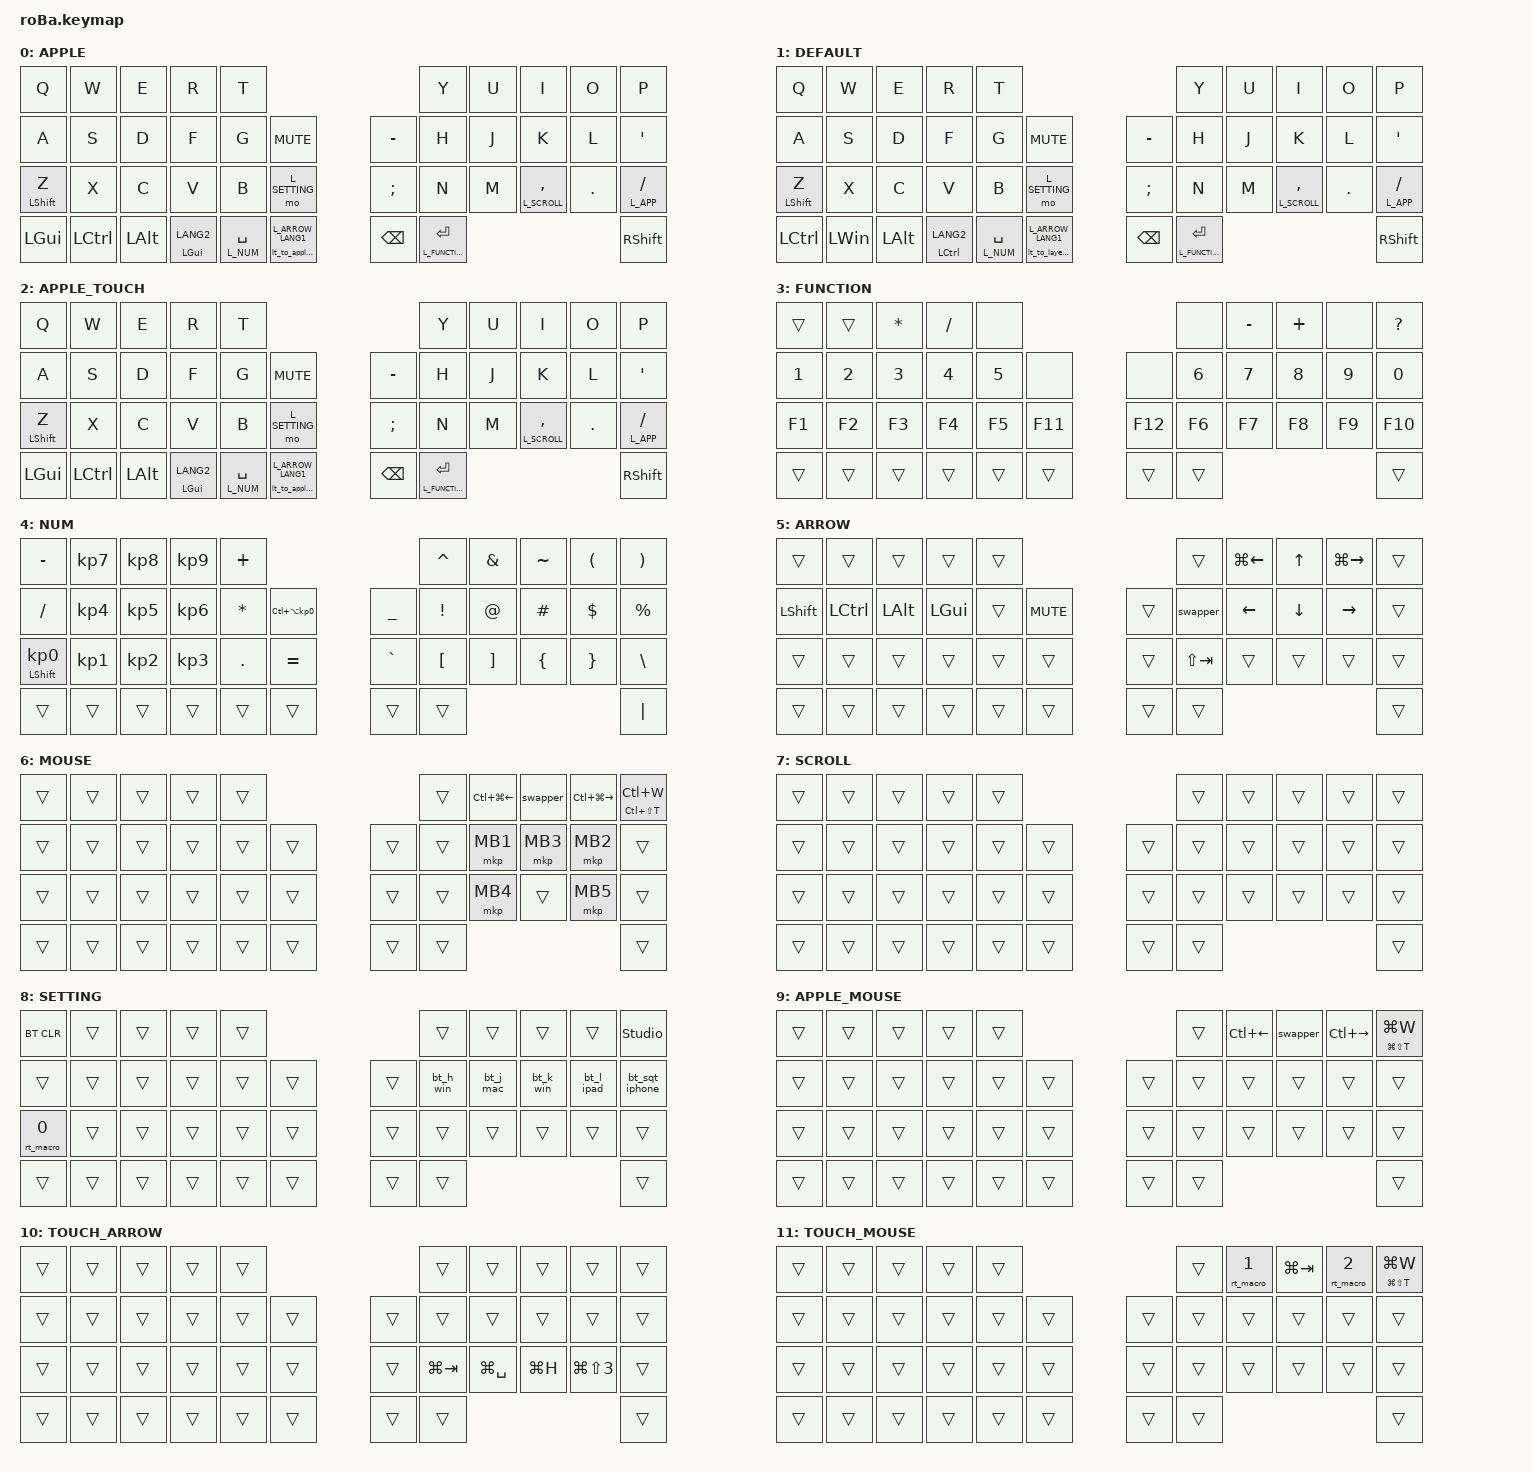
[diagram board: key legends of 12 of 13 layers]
#include <behaviors/runtime-sensor-rotate.dtsi>
#include <behaviors.dtsi>
#include <dt-bindings/zmk/bt.h>
#include <dt-bindings/zmk/keys.h>
#include <dt-bindings/zmk/pointing.h>

#undef ZMK_POINTING_DEFAULT_SCRL_VAL

#define ZMK_POINTING_DEFAULT_SCRL_VAL 80
#define L_DEFAULT      1
#define L_APPLE        0
#define L_APPLE_TOUCH  2
#define L_FUNCTION     3
#define L_NUM          4
#define L_ARROW        5
#define L_MOUSE        6
#define L_SCROLL       7
#define L_SETTING      8
#define L_APPLEMOUSE   9
#define L_TOUCH_ARROW  10
#define L_TOUCH_MOUSE  11
#define L_APP          12

&mt {
    flavor = "balanced";
    quick-tap-ms = <0>;
};

&trackball {
    automouse-layer = <L_MOUSE>;
    scroll-layers = <L_SCROLL>;

    // arrows {
    //     layers = <3>;
    //     bindings =
    //         <&kp RIGHT_ARROW>,
    //         <&kp LEFT_ARROW>,
    //         <&kp UP_ARROW>,
    //         <&kp DOWN_ARROW>;
    //     tick = <10>;
    //     wait-ms = <5>;
    //     tap-ms = <5>;
    // };
};

/ {
    combos {
        compatible = "zmk,runtime-combos";

        tab {
            bindings = <&kp TAB>;
            key-positions = <11 10>;
        };

        esc {
            bindings = <&kp ESCAPE>;
            key-positions = <0 1>;
        };

        backspace {
            bindings = <&kp BACKSPACE>;
            key-positions = <9 8>;
        };

        delete {
            bindings = <&kp DELETE>;
            key-positions = <20 21>;
        };

        redo_win {
            bindings = <&kp LC(LS(Z))>;
            key-positions = <22 23 24>;
            layers = <L_DEFAULT L_MOUSE>;
        };

        redo_apple {
            bindings = <&kp LG(LS(Z))>;
            key-positions = <22 23 24>;
            layers = <L_APPLE L_APPLEMOUSE L_APPLE_TOUCH L_TOUCH_MOUSE>;
        };
    };

    macros {
        to_layer_0: to_layer_0 {
            compatible = "zmk,behavior-macro-one-param";
            #binding-cells = <1>;
            bindings = <&to L_DEFAULT &macro_param_1to1 &kp MACRO_PLACEHOLDER>;
            label = "TO_LAYER_0";
        };

        to_apple_default: to_apple_default {
            compatible = "zmk,behavior-macro-one-param";
            #binding-cells = <1>;
            bindings = <&to L_APPLE &macro_param_1to1 &kp MACRO_PLACEHOLDER>;
            label = "TO_APPLE_DEFAULT";
        };

        to_apple_touch: to_apple_touch {
            compatible = "zmk,behavior-macro-one-param";
            #binding-cells = <1>;
            bindings = <&to L_APPLE_TOUCH &macro_param_1to1 &kp MACRO_PLACEHOLDER>;
            label = "TO_APPLE_TOUCH";
        };

        // BT profile -> base-layer routing. Key position fixed (H/J/K/L/SQT),
        // BT_SEL number fixed; only the &to base-layer differs (案B 2026-06-24).

        bt_h_win: bt_h_win {
            compatible = "zmk,behavior-macro";
            #binding-cells = <0>;
            bindings = <&bt BT_SEL 4 &to L_DEFAULT>;
            label = "BT_H_WIN";
        };

        bt_j_mac: bt_j_mac {
            compatible = "zmk,behavior-macro";
            #binding-cells = <0>;
            bindings = <&bt BT_SEL 0 &to L_APPLE>;
            label = "BT_J_MAC";
        };

        bt_k_win: bt_k_win {
            compatible = "zmk,behavior-macro";
            #binding-cells = <0>;
            bindings = <&bt BT_SEL 1 &to L_DEFAULT>;
            label = "BT_K_WIN";
        };

        bt_l_ipad: bt_l_ipad {
            compatible = "zmk,behavior-macro";
            #binding-cells = <0>;
            bindings = <&bt BT_SEL 2 &to L_APPLE_TOUCH>;
            label = "BT_L_IPAD";
        };

        bt_sqt_iphone: bt_sqt_iphone {
            compatible = "zmk,behavior-macro";
            #binding-cells = <0>;
            bindings = <&bt BT_SEL 3 &to L_APPLE_TOUCH>;
            label = "BT_SQT_IPHONE";
        };
    };

    behaviors {
        rt_macro: rt_macro {
            compatible = "zmk,behavior-runtime-macro";
            #binding-cells = <1>;
        };

        lt_to_layer_0: lt_to_layer_0 {
            compatible = "zmk,behavior-runtime-hold-tap";
            label = "LAYER_TAP_TO_0";
            bindings = <&mo>, <&to_layer_0>;

            #binding-cells = <2>;
            tapping-term-ms = <200>;
        };

        lt_to_apple_default: lt_to_apple_default {
            compatible = "zmk,behavior-runtime-hold-tap";
            label = "LAYER_TAP_TO_APPLE";
            bindings = <&mo>, <&to_apple_default>;

            #binding-cells = <2>;
            tapping-term-ms = <200>;
        };

        lt_to_apple_touch: lt_to_apple_touch {
            compatible = "zmk,behavior-runtime-hold-tap";
            label = "LAYER_TAP_TO_APPLE_TOUCH";
            bindings = <&mo>, <&to_apple_touch>;

            #binding-cells = <2>;
            tapping-term-ms = <200>;
        };

        // 英数: 1回押し = 英数 + ベースへ戻る、長押し = 修飾キー (2026-11-11)。
        // 標準の hold-tap にしてあるのは、runtime-hold-tap の保存スロット番号
        // (lt_to_* の 0-2) をずらさないため。

        mod_eisu_apple: mod_eisu_apple {
            compatible = "zmk,behavior-hold-tap";
            #binding-cells = <2>;
            flavor = "balanced";
            tapping-term-ms = <200>;
            quick-tap-ms = <0>;
            bindings = <&kp>, <&to_apple_default>;
        };

        mod_eisu_touch: mod_eisu_touch {
            compatible = "zmk,behavior-hold-tap";
            #binding-cells = <2>;
            flavor = "balanced";
            tapping-term-ms = <200>;
            quick-tap-ms = <0>;
            bindings = <&kp>, <&to_apple_touch>;
        };

        mod_eisu_win: mod_eisu_win {
            compatible = "zmk,behavior-hold-tap";
            #binding-cells = <2>;
            flavor = "balanced";
            tapping-term-ms = <200>;
            quick-tap-ms = <0>;
            bindings = <&kp>, <&to_layer_0>;
        };

        encoder_msc_down_up: encoder_msc_down_up {
            compatible = "zmk,behavior-sensor-rotate";
            label = "ENCODER_MSC_DOWN_UP";
            #sensor-binding-cells = <0>;
            bindings = <&msc SCRL_UP>, <&msc SCRL_DOWN>;

            tap-ms = <50>;
        };

        encoder_vol_down_up: encoder_vol_down_up {
            compatible = "zmk,behavior-runtime-sensor-rotate";
            label = "ENCODER_VOL_DOWN_UP";
            #sensor-binding-cells = <0>;
            cw-binding = <&kp C_VOLUME_DOWN>;
            ccw-binding = <&kp C_VOLUME_UP>;
            tap-ms = <20>;
        };

        swapper: swapper {
            compatible = "zmk,behavior-smart-toggle";
            #binding-cells = <0>;
            bindings = <&kp LALT>, <&kp TAB>;
            ignored-key-positions = <29>;
        };
    };

    conditional_layers {
        compatible = "zmk,runtime-conditional-layers";

        apple_mouse {
            if-layers = <L_APPLE L_MOUSE>;
            then-layer = <L_APPLEMOUSE>;
        };

        touch_mouse {
            if-layers = <L_APPLE_TOUCH L_MOUSE>;
            then-layer = <L_TOUCH_MOUSE>;
        };

        touch_arrow {
            if-layers = <L_APPLE_TOUCH L_ARROW>;
            then-layer = <L_TOUCH_ARROW>;
        };
    };

    keymap {
        compatible = "zmk,keymap";

        APPLE {
            bindings = <
&kp Q             &kp W      &kp E         &kp R                                 &kp T                                                                   &kp Y                 &kp U  &kp I               &kp O    &kp P
&kp A             &kp S      &kp D         &kp F                                 &kp G            &kp K_MUTE                              &kp MINUS      &kp H                 &kp J  &kp K               &kp L    &kp SQT
&mt LEFT_SHIFT Z  &kp X      &kp C         &kp V                                 &kp B            &mo L_SETTING                           &kp SEMICOLON  &kp N                 &kp M  &lt L_SCROLL COMMA  &kp DOT  &lt L_APP SLASH
&kp LEFT_GUI      &kp LCTRL  &kp LEFT_ALT  &mod_eisu_apple LEFT_GUI LANG2        &lt L_NUM SPACE  &lt_to_apple_default L_ARROW LANG1      &kp BACKSPACE  &lt L_FUNCTION ENTER                                      &kp RIGHT_SHIFT
            >;

            sensor-bindings = <&encoder_vol_down_up>;
        };

        DEFAULT {
            bindings = <
&kp Q               &kp W         &kp E         &kp R                           &kp T                                                             &kp Y                 &kp U  &kp I               &kp O    &kp P
&kp A               &kp S         &kp D         &kp F                           &kp G            &kp K_MUTE                        &kp MINUS      &kp H                 &kp J  &kp K               &kp L    &kp SQT
&mt LEFT_SHIFT Z    &kp X         &kp C         &kp V                           &kp B            &mo L_SETTING                     &kp SEMICOLON  &kp N                 &kp M  &lt L_SCROLL COMMA  &kp DOT  &lt L_APP SLASH
&kp LCTRL           &kp LEFT_WIN  &kp LEFT_ALT  &mod_eisu_win LEFT_CONTROL LANG2  &lt L_NUM SPACE  &lt_to_layer_0 L_ARROW LANG1      &kp BACKSPACE  &lt L_FUNCTION ENTER                                      &kp RIGHT_SHIFT
            >;

            sensor-bindings = <&encoder_vol_down_up>;
        };

        APPLE_TOUCH {
            bindings = <
&kp Q             &kp W      &kp E         &kp R                               &kp T                                                                 &kp Y                 &kp U  &kp I               &kp O    &kp P
&kp A             &kp S      &kp D         &kp F                               &kp G            &kp K_MUTE                            &kp MINUS      &kp H                 &kp J  &kp K               &kp L    &kp SQT
&mt LEFT_SHIFT Z  &kp X      &kp C         &kp V                               &kp B            &mo L_SETTING                         &kp SEMICOLON  &kp N                 &kp M  &lt L_SCROLL COMMA  &kp DOT  &lt L_APP SLASH
&kp LEFT_GUI      &kp LCTRL  &kp LEFT_ALT  &mod_eisu_touch LEFT_GUI LANG2      &lt L_NUM SPACE  &lt_to_apple_touch L_ARROW LANG1      &kp BACKSPACE  &lt L_FUNCTION ENTER                                      &kp RIGHT_SHIFT
            >;

            sensor-bindings = <&encoder_vol_down_up>;
        };

        FUNCTION {
            bindings = <
&trans        &trans        &kp ASTERISK  &kp SLASH     &none                               &none         &kp MINUS     &kp PLUS      &none         &kp QUESTION
&kp NUMBER_1  &kp NUMBER_2  &kp NUMBER_3  &kp NUMBER_4  &kp NUMBER_5  &none        &none    &kp NUMBER_6  &kp NUMBER_7  &kp NUMBER_8  &kp NUMBER_9  &kp NUMBER_0
&kp F1        &kp F2        &kp F3        &kp F4        &kp F5        &kp F11      &kp F12  &kp F6        &kp F7        &kp F8        &kp F9        &kp F10
&trans        &trans        &trans        &trans        &trans        &trans       &trans   &trans                                                  &trans
            >;
        };

        NUM {
            bindings = <
&kp MINUS                   &kp KP_NUMBER_7  &kp KP_NUMBER_8  &kp KP_NUMBER_9  &kp PLUS                                                   &kp CARET         &kp AMPERSAND      &kp TILDE       &kp LEFT_PARENTHESIS  &kp RIGHT_PARENTHESIS
&kp SLASH                   &kp KP_NUMBER_4  &kp KP_NUMBER_5  &kp KP_NUMBER_6  &kp ASTERISK  &kp LC(LA(KP_NUMBER_0))      &kp UNDERSCORE  &kp EXCLAMATION   &kp AT_SIGN        &kp HASH        &kp DOLLAR            &kp PERCENT
&mt LEFT_SHIFT KP_NUMBER_0  &kp KP_NUMBER_1  &kp KP_NUMBER_2  &kp KP_NUMBER_3  &kp PERIOD    &kp EQUAL                    &kp GRAVE       &kp LEFT_BRACKET  &kp RIGHT_BRACKET  &kp LEFT_BRACE  &kp RIGHT_BRACE       &kp BACKSLASH
&trans                      &trans           &trans           &trans           &trans        &trans                       &trans          &trans                                                                     &kp PIPE
            >;
        };

        ARROW {
            bindings = <
&trans          &trans         &trans        &trans        &trans                          &trans    &kp LG(LEFT)    &kp UP_ARROW    &kp LG(RIGHT)    &trans
&kp LEFT_SHIFT  &kp LCTRL      &kp LEFT_ALT  &kp LEFT_GUI  &trans  &kp C_MUTE      &trans  &swapper  &kp LEFT_ARROW  &kp DOWN_ARROW  &kp RIGHT_ARROW  &trans
&trans          &trans         &trans        &trans        &trans  &trans          &trans  &kp LS(TAB)  &trans          &trans          &trans           &trans
&trans          &trans         &trans        &trans        &trans  &trans          &trans  &trans                                                     &trans
            >;

            sensor-bindings = <&encoder_vol_down_up>;
        };

        MOUSE {
            bindings = <
&trans  &trans  &trans  &trans  &trans                      &trans  &kp LC(LG(LEFT))  &swapper  &kp LC(LG(RIGHT))  &mt LC(LS(T)) LC(W)
&trans  &trans  &trans  &trans  &trans  &trans      &trans  &trans  &mkp MB1          &mkp MB3     &mkp MB2           &trans
&trans  &trans  &trans  &trans  &trans  &trans      &trans  &trans  &mkp MB4          &trans       &mkp MB5           &trans
&trans  &trans  &trans  &trans  &trans  &trans      &trans  &trans                                                    &trans
            >;
        };

        SCROLL {
            bindings = <
&trans  &trans  &trans  &trans  &trans                      &trans  &trans  &trans  &trans  &trans
&trans  &trans  &trans  &trans  &trans  &trans      &trans  &trans  &trans  &trans  &trans  &trans
&trans  &trans  &trans  &trans  &trans  &trans      &trans  &trans  &trans  &trans  &trans  &trans
&trans  &trans  &trans  &trans  &trans  &trans      &trans  &trans                          &trans
            >;
        };

        SETTING {
            bindings = <
&bt BT_CLR   &trans  &trans  &trans  &trans                      &trans     &trans     &trans     &trans      &studio_unlock
&trans       &trans  &trans  &trans  &trans  &trans      &trans  &bt_h_win  &bt_j_mac  &bt_k_win  &bt_l_ipad  &bt_sqt_iphone
&rt_macro 0  &trans  &trans  &trans  &trans  &trans      &trans  &trans     &trans     &trans     &trans      &trans
&trans       &trans  &trans  &trans  &trans  &trans      &trans  &trans                                       &trans
            >;
        };

        APPLE_MOUSE {
            bindings = <
&trans  &trans  &trans  &trans  &trans                      &trans  &kp LC(LEFT)  &swapper  &kp LC(RIGHT)  &mt LG(LS(T)) LG(W)
&trans  &trans  &trans  &trans  &trans  &trans      &trans  &trans  &trans        &trans       &trans         &trans
&trans  &trans  &trans  &trans  &trans  &trans      &trans  &trans  &trans        &trans       &trans         &trans
&trans  &trans  &trans  &trans  &trans  &trans      &trans  &trans                                            &trans
            >;
        };

        TOUCH_ARROW {
            bindings = <
&trans  &trans  &trans  &trans  &trans                      &trans  &trans       &trans         &trans      &trans
&trans  &trans  &trans  &trans  &trans  &trans      &trans  &trans  &trans       &trans         &trans      &trans
&trans  &trans  &trans  &trans  &trans  &trans      &trans  &kp LG(TAB)  &kp LG(SPACE)  &kp LG(H)  &kp LG(LS(N3))  &trans
&trans  &trans  &trans  &trans  &trans  &trans      &trans  &trans                                          &trans
            >;
        };

        TOUCH_MOUSE {
            bindings = <
&trans  &trans  &trans  &trans  &trans                      &trans  &rt_macro 1  &kp LG(TAB)  &rt_macro 2  &mt LG(LS(T)) LG(W)
&trans  &trans  &trans  &trans  &trans  &trans      &trans  &trans  &trans       &trans       &trans       &trans
&trans  &trans  &trans  &trans  &trans  &trans      &trans  &trans  &trans       &trans       &trans       &trans
&trans  &trans  &trans  &trans  &trans  &trans      &trans  &trans                                         &trans
            >;
        };

        APP {
            bindings = <
&kp LA(N1)  &kp LA(N2)  &kp LA(N3)  &trans  &trans                      &trans  &trans  &trans  &trans  &trans
&kp LA(N4)  &kp LA(N5)  &kp LA(N6)  &trans  &trans  &trans      &trans  &kp F13  &kp F14  &kp F15  &trans  &trans
&kp LA(N7)  &kp LA(N8)  &trans      &trans  &trans  &trans      &trans  &kp F16  &kp F17  &kp F18  &trans  &trans
&trans      &trans      &trans      &trans  &trans  &trans      &trans  &trans                          &trans
            >;
        };
    };
};
